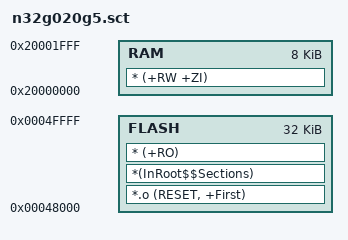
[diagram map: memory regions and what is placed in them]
; CHIP: N32G020G5, FLASH: 32K, RAM: 8K

LR_ROM1 0x048000 0x008000     ; load region
{
    FLASH 0x048000 0x008000   ; load address = execution address
    {
        *.o (RESET, +First)
        *(InRoot$$Sections)
   	    * (+RO)
    }

    RAM 0x20000000 0x002000  ; RAM
    {
   	    * (+RW +ZI)
    }
}
